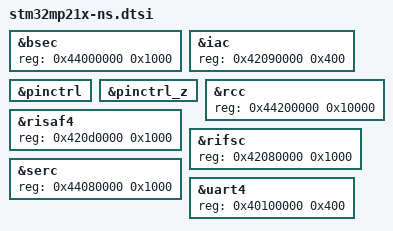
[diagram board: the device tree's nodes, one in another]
// SPDX-License-Identifier: (GPL-2.0-only OR BSD-3-Clause)
/*
 * Copyright (C) STMicroelectronics 2025 - All Rights Reserved
 *
 * This file allows to overwrite stm32mp21X.dtsi to change secure reg
 * properties by non secure value (for soc devices)
 */

&bsec {
	reg = <0x44000000 0x1000>;
};

&iac {
	reg = <0x42090000 0x400>;
};

&pinctrl {
	ranges = <0 0x44240000 0xa0400>;
};

&pinctrl_z {
	ranges = <0 0x46200000 0x400>;
};

&rcc {
	reg = <0x44200000 0x10000>;
};

&risaf4 {
	reg = <0x420d0000 0x1000>;
};

&rifsc {
	reg = <0x42080000 0x1000>;
};

&serc {
	reg = <0x44080000 0x1000>;
};

&uart4 {
	reg = <0x40100000 0x400>;
};
